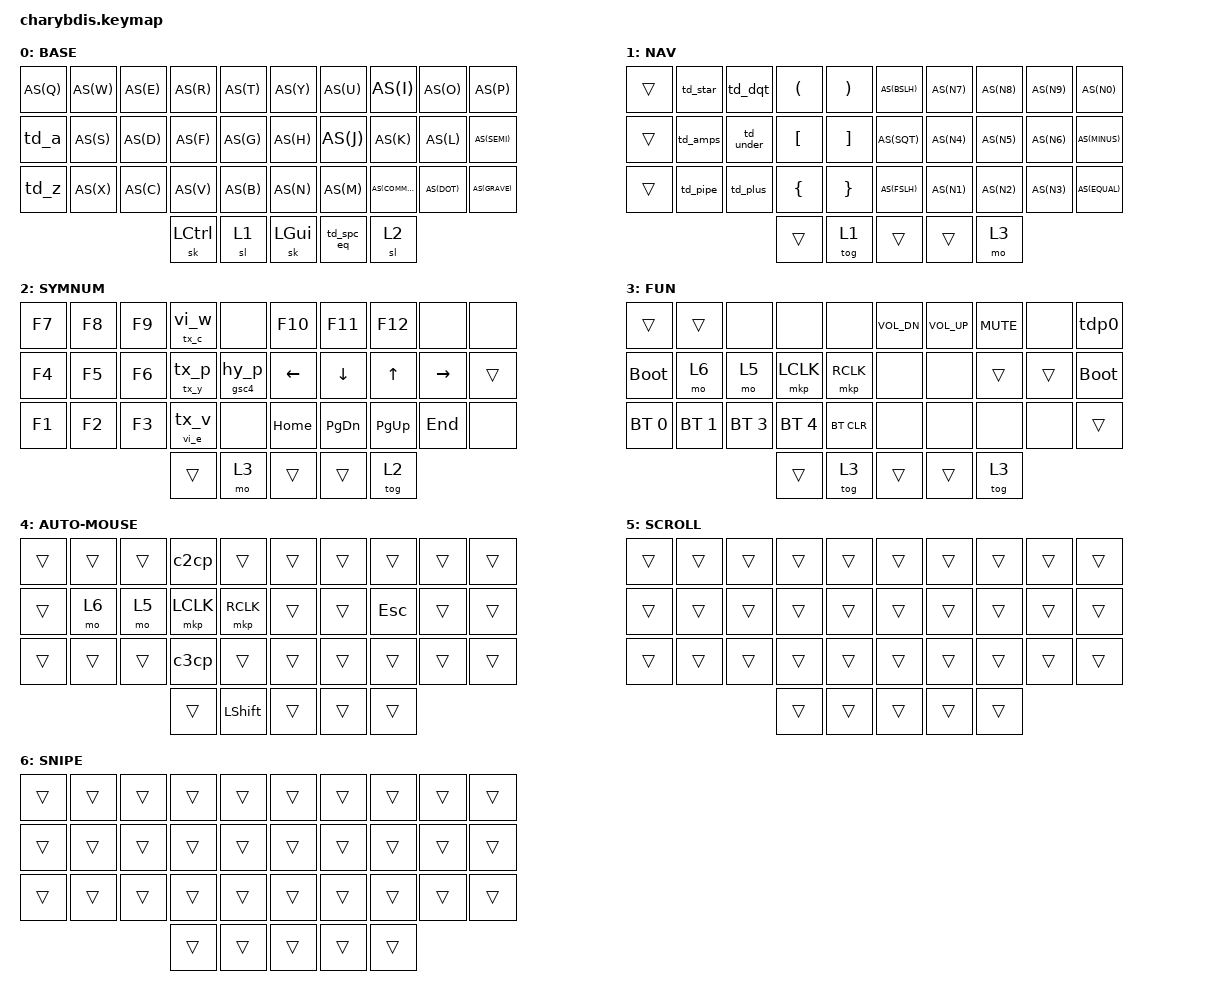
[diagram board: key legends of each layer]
#include <behaviors/mouse_keys.dtsi>
#include <behaviors.dtsi>
#include <dt-bindings/zmk/bt.h>
#include <dt-bindings/zmk/keys.h>
#include <dt-bindings/zmk/mouse.h>
#include <dt-bindings/zmk/outputs.h>

#define AS(keycode) &as LS(keycode) keycode     // Autoshift Macro

#define SPC_WRAP(macro_name, content) \
        macro_name: macro_name { \
            compatible = "zmk,behavior-macro"; \
            #binding-cells = <0>; \
            wait-ms = <25>; \
            tap-ms = <25>; \
            bindings = <&macro_tap &kp SPACE content &kp SPACE>; \
        }

#define TD_SPC_WRAP_2(td_name, prime_key, macro_name) \
        td_name: td_name { \
            compatible = "zmk,behavior-tap-dance"; \
            #binding-cells = <0>; \
            tapping-term-ms = <200>; \
            bindings = <&kp prime_key>, <&macro_name>; \
        }

// Longer time out for oneshot keys
&sl {
    release-after-ms = <2000>;
};
&sk {
    release-after-ms = <2000>;
};

/ {
    chosen { zmk,matrix_transform = &five_column_transform; };
};

/ {
    macros {
        vi_w: vi_w {
            label = "VIM_SAVE";
            compatible = "zmk,behavior-macro";
            #binding-cells = <0>;
            wait-ms = <40>;
            tap-ms = <40>;
            bindings
                = <&macro_tap &kp ESC &kp COLON &kp W &kp ENTER>
                ;
        };
        vi_e: vi_e {
            label = "VIM_RELOADE_BUFFER";
            compatible = "zmk,behavior-macro";
            #binding-cells = <0>;
            wait-ms = <40>;
            tap-ms = <40>;
            bindings
                = <&macro_tap &kp ESC &kp COLON &kp E &kp LS(N1) &kp ENTER>
                ;
        };
        tx_c: tx_c {
            label = "TMUX_COPY_MODE";
            compatible = "zmk,behavior-macro";
            #binding-cells = <0>;
            wait-ms = <40>;
            tap-ms = <40>;
            bindings
                = <&macro_tap &kp LC(B) &kp LBKT>
                ;
        };
        tx_p: tx_p {
            label = "TMUX_PREV_PANE";
            compatible = "zmk,behavior-macro";
            #binding-cells = <0>;
            wait-ms = <40>;
            tap-ms = <40>;
            bindings
                = <&macro_tap &kp LC(B) &kp SEMI>
                ;
        };
        tx_y: tx_y {
            label = "TMUX_PREV_PANE_MAX";
            compatible = "zmk,behavior-macro";
            #binding-cells = <0>;
            wait-ms = <40>;
            tap-ms = <40>;
            bindings
                = <&macro_tap &kp LC(B) &kp Y>
                ;
        };
        tx_v: tx_v {
            label = "TMUX_PREV_PASTE";
            compatible = "zmk,behavior-macro";
            #binding-cells = <0>;
            wait-ms = <40>;
            tap-ms = <40>;
            bindings
                = <&macro_tap &kp LC(B) &kp COLON &kp P &kp A &kp ENTER>
                ;
        };
        hy_p: hy_p {
            label = "HYPER_P";
            compatible = "zmk,behavior-macro";
            #binding-cells = <0>;
            wait-ms = <40>;
            tap-ms = <40>;
            bindings
                = <&macro_tap &kp LG(LA(LS(LC(P))))>
                ;
        };
        gsc4: gsc4 {
            label = "MAC_OS_SCREENSHOT_4";
            compatible = "zmk,behavior-macro";
            #binding-cells = <0>;
            wait-ms = <40>;
            tap-ms = <40>;
            bindings
                = <&macro_tap &kp LG(LS(LC(N4)))>
                ;
        };
        pri0: pri0 {
            label = "PRIVATE_KEY_SEQ_0";
            compatible = "zmk,behavior-macro";
            #binding-cells = <0>;
            wait-ms = <40>;
            tap-ms = <40>;
            bindings
                = <&macro_tap 
                    &kp LS(Z) &kp C &kp T &kp D &kp L &kp A &kp M &kp N &kp U 
                    &kp X &kp D &kp E &kp X &kp D &kp Z &kp O &kp G &kp D &kp M 
                    &kp Z>
                ;
        };
        pri1: pri1 {
            label = "PRIVATE_KEY_SEQ_1";
            compatible = "zmk,behavior-macro";
            #binding-cells = <0>;
            wait-ms = <40>;
            tap-ms = <40>;
            bindings
                = <&macro_tap &kp BSPC>
                , <&macro_wait_time 3500>
                , <&pri0>
                ;
        };
        pri2: pri2 {
            label = "PRIVATE_KEY_SEQ_2";
            compatible = "zmk,behavior-macro";
            #binding-cells = <0>;
            wait-ms = <40>;
            tap-ms = <40>;
            bindings
                = <&macro_tap 
                    &kp C &kp T &kp D &kp L &kp A &kp M &kp N &kp U 
                    &kp Z>
                ;
        };
        // Click and copy
        c2cp: c2cp {
            label = "DOUBLE_CLICK_CMD_C";
            compatible = "zmk,behavior-macro";
            #binding-cells = <0>;
            wait-ms = <40>;
            bindings
                = <&macro_tap &mkp LCLK &mkp LCLK>
                , <&macro_wait_time 300>
                , <&macro_tap &kp LG(C)>
                ;
        };
        c3cp: c3cp {
            label = "TRIPLE_CLICK_CMD_C";
            compatible = "zmk,behavior-macro";
            #binding-cells = <0>;
            wait-ms = <40>;
            bindings
                = <&macro_tap &mkp LCLK &mkp LCLK &mkp LCLK>
                , <&macro_wait_time 300>
                , <&macro_tap &kp LG(C)>
                ;
        };

        SPC_WRAP(spc_eq, &kp EQUAL);
        SPC_WRAP(spc_mi, &kp MINUS);
        SPC_WRAP(spc_pl, &kp PLUS);
        SPC_WRAP(spc_st, &kp STAR);
        SPC_WRAP(spc_am, &kp AMPS &kp AMPS);
        SPC_WRAP(spc_pi, &kp PIPE &kp PIPE);

        tri_dqt: tri_dqt {
            label = "TRIPLE_DOUBLE_QUOTE";
            compatible = "zmk,behavior-macro";
            #binding-cells = <0>;
            wait-ms = <40>;
            bindings = <&macro_tap &kp DQT &kp DQT &kp DQT>;
        };
    };

    behaviors {
        tdsc: tap_dance_toggle_scroll {
            label = "TD_TOGGLE_SCROLL";
            compatible = "zmk,behavior-tap-dance";
            #binding-cells = <0>;
            tapping-term-ms = <175>;
            bindings = <&mo 5>, <&tog 5>;
        };

        tdsn: tap_dance_toggle_sniping {
            label = "TD_TOGGLE_SNIPING";
            compatible = "zmk,behavior-tap-dance";
            #binding-cells = <0>;
            tapping-term-ms = <175>;
            bindings = <&mo 6>, <&tog 6>;
        };

        as: auto_shift {
            label = "AUTO_SHIFT";
            compatible = "zmk,behavior-hold-tap";
            #binding-cells = <2>;
            tapping_term_ms = <155>;
            quick_tap_ms = <154>;
            flavor = "tap-preferred";
            bindings = <&kp>, <&kp>;
        };

        ht_r: hold_tap_at_r {
            label = "HOLD_TAP_AT_R";
            compatible = "zmk,behavior-hold-tap";
            #binding-cells = <2>;
            tapping_term_ms = <155>;
            quick_tap_ms = <120>;
            flavor = "tap-preferred";
            bindings = <&tx_c>, <&vi_w>;
        };

        ht_f: hold_tap_at_f {
            label = "HOLD_TAP_AT_F";
            compatible = "zmk,behavior-hold-tap";
            #binding-cells = <2>;
            tapping_term_ms = <155>;
            quick_tap_ms = <120>;
            flavor = "tap-preferred";
            bindings = <&tx_y>, <&tx_p>;
        };

        ht_v: hold_tap_at_v {
            label = "HOLD_TAP_AT_V";
            compatible = "zmk,behavior-hold-tap";
            #binding-cells = <2>;
            tapping_term_ms = <155>;
            quick_tap_ms = <120>;
            flavor = "tap-preferred";
            bindings = <&vi_e>, <&tx_v>;
        };

        ht_g: hold_tap_at_g {
            label = "HOLD_TAP_AT_G";
            compatible = "zmk,behavior-hold-tap";
            #binding-cells = <2>;
            tapping_term_ms = <155>;
            quick_tap_ms = <120>;
            flavor = "tap-preferred";
            bindings = <&gsc4>, <&hy_p>;
        };

        ht_p: hold_tap_at_p {
            label = "HOLD_TAP_AT_P";
            compatible = "zmk,behavior-hold-tap";
            #binding-cells = <2>;
            tapping_term_ms = <155>;
            quick_tap_ms = <120>;
            flavor = "tap-preferred";
            bindings = <&pri2>, <&pri0>;
        };

        tdp0: tap_dance_private_seq_02 {
            label = "TD_PRIVATE_SEQ_02";
            compatible = "zmk,behavior-tap-dance";
            #binding-cells = <0>;
            tapping-term-ms = <175>;
            bindings = <&none>, <&ht_p 0 0>;
        };
        
        ht_32: hold_tri_click_tap_double_click {
            label = "HOLD_TRI_TAP_DOUBLE";
            compatible = "zmk,behavior-hold-tap";
            #binding-cells = <2>;
            tapping-term-ms = <200>;
            flavor = "tap-preferred";
            bindings = <&c3cp>, <&c2cp>;
        };

        TD_SPC_WRAP_2(td_spc_eq, SPACE, spc_eq);
        TD_SPC_WRAP_2(td_under, UNDER, spc_mi);
        TD_SPC_WRAP_2(td_plus, PLUS, spc_pl);
        TD_SPC_WRAP_2(td_dqt, DQT, tri_dqt);
        TD_SPC_WRAP_2(td_star, STAR, spc_st);
        TD_SPC_WRAP_2(td_amps, AMPS, spc_am);
        TD_SPC_WRAP_2(td_pipe, PIPE, spc_pi);
        
        td_z: tap_dance_z_alt {
            compatible = "zmk,behavior-tap-dance";
            #binding-cells = <0>;
            tapping-term-ms = <175>;
            bindings = <&mt LALT Z>, <&as Z LS(Z)>;
        };
        td_a: tap_dance_a_shift {
            compatible = "zmk,behavior-tap-dance";
            #binding-cells = <0>;
            tapping-term-ms = <175>;
            bindings = <&mt LSHFT A>, <&as A LS(A)>;
        };
    };

    combos {
        compatible = "zmk,combos";
        // Tmux
        combo_ctrl_b {
            timeout-ms = <25>;
            key-positions = <12 2>; // D, E
            bindings = <&kp LC(B)>;
        };

        // Track ball and mouse clicks
        combo_mo_scroll {
            timeout-ms = <25>;
            key-positions = <11 1>; // S, W
            bindings = <&tdsc>; //<&mo 5>;
        };
        combo_mo_snipe {
            timeout-ms = <25>;
            key-positions = <8 18>; // O, L
            bindings = <&tdsn>; //<&mo 6>;
        };
        combo_left_click {
            timeout-ms = <25>;
            key-positions = <12 13>; // D, F
            bindings = <&mkp LCLK>;
        };
        combo_right_click {
            timeout-ms = <25>;
            key-positions = <13 14>; // F, G
            bindings = <&mkp RCLK>;
        };
        combo_tog_3 {
            timeout-ms = <25>;
            key-positions = <11 21>; // S, X
            bindings = <&tog 3>;
        };


        // Enter/ESC ...
        combo_enter {
            timeout-ms = <25>;
            key-positions = <7 17>; // I, K
            bindings = <&kp ENTER>;
        };
        combo_shift_enter {
            timeout-ms = <25>;
            key-positions = <17 27>; // K, COMMA
            bindings = <&kp LS(ENTER)>;
        };
        combo_tab {
            timeout-ms = <25>;
            key-positions = <16 26>; // J, M
            bindings = <&kp TAB>;
        };
        combo_caps_word {
            timeout-ms = <25>;
            key-positions = <15 25>; // H, N
            bindings = <&caps_word>;
        };
        combo_esc_1 {
            timeout-ms = <25>;
            key-positions = <13 23>; // F, V
            bindings = <&kp ESC>;
        };
        combo_esc_2 {
            timeout-ms = <25>;
            key-positions = <11 18>; // S, L
            bindings = <&kp ESC>;
        };
        combo_bspc {
            timeout-ms = <25>;
            key-positions = <3 13>; // R, F
            bindings = <&kp BSPC>;
        };
        combo_del {
            timeout-ms = <25>;
            key-positions = <4 14>; // T, G
            bindings = <&kp DEL>;
        };

        // Lock screen (MacOS)
        combo_cmd_ctrl_q {
            timeout-ms = <25>;
            key-positions = <13 23 14 24>; // F, V, G, B
            bindings = <&kp LG(LC(Q))>;
        };

        combo_alt_space {
            timeout-ms = <25>;
            key-positions = <16 17>; // J, K
            bindings = <&kp LA(SPACE)>;
        };

        combo_ctrl_alt_space {
            timeout-ms = <25>;
            key-positions = <14 24>; // G, B
            bindings = <&kp LA(LC(SPACE))>;
        };

        combo_ctrl_alt_shift_space {
            timeout-ms = <25>;
            key-positions = <18 28>; // L, .(DOT)
            bindings = <&kp LA(LC(LS(SPACE)))>;
        };

        combo_private_seq_1 {
            timeout-ms = <25>;
            key-positions = <15 16 25 26>; // H, J, N, M
            bindings = <&pri1>;
        };
        
        // Oneshot mods
        combo_shift {
            timeout-ms = <25>;
            key-positions = <11 13>; // S, F
            bindings = <&sk LSHFT>;
        };
        combo_alt {
            timeout-ms = <25>;
            key-positions = <17 18>; // K, L
            bindings = <&sk LALT>;
        };
        // M, A is used for alt-shift-down
        combo_gui_shift {
            timeout-ms = <25>;
            key-positions = <26 11>; // M, S
            bindings = <&sk LG(LSHFT)>;
        };
        combo_gui_alt {
            timeout-ms = <40>;
            key-positions = <26 13>; // M, F
            bindings = <&sk LG(LALT)>;
        };
        combo_gui_ctrl {
            timeout-ms = <40>;
            key-positions = <26 22>; // M, C
            bindings = <&sk LG(LCTRL)>;
        };
        combo_gui_shift_alt {
            timeout-ms = <30>;
            key-positions = <26 12>; // M, D
            bindings = <&sk LG(LS(LALT))>;
        };
        combo_gui_shift_ctrl {
            timeout-ms = <40>;
            key-positions = <26 21>; // M, X
            bindings = <&sk LG(LS(LCTRL))>;
        };
        combo_gui_alt_ctrl {
            timeout-ms = <40>;
            key-positions = <26 23>; // M, V
            bindings = <&sk LG(LA(LCTRL))>;
        };
        combo_hyper {
            timeout-ms = <40>;
            key-positions = <26 1>; // M, W
            bindings = <&sk LG(LS(LA(LCTRL)))>;
        };
        combo_meh {
            timeout-ms = <40>;
            key-positions = <23 15>; // V, H
            bindings = <&sk LS(LA(LCTRL))>;
        };
        combo_alt_ctrl {
            timeout-ms = <40>;
            key-positions = <23 16>; // V, J
            bindings = <&sk LA(LCTRL)>;
        };
        combo_alt_shift {
            timeout-ms = <40>;
            key-positions = <23 17>; // V, K
            bindings = <&sk LA(LSHFT)>;
        };
        combo_shift_ctrl {
            timeout-ms = <40>;
            key-positions = <23 18>; // V, L
            bindings = <&sk LC(LSHFT)>;
        };
        /*
        // Alt / Shift with arrows
        combo_alt_left_arrow {
            timeout-ms = <40>;
            key-positions = <10 15>; // A, H
            bindings = <&kp LA(LEFT)>;
        };
        combo_alt_down_arrow {
            timeout-ms = <40>;
            key-positions = <10 16>; // A, J
            bindings = <&kp LA(DOWN)>;
        };
        combo_alt_up_arrow {
            timeout-ms = <40>;
            key-positions = <10 17>; // A, K
            bindings = <&kp LA(UP)>;
        };
        combo_alt_right_arrow {
            timeout-ms = <40>;
            key-positions = <10 18>; // A, L
            bindings = <&kp LA(RIGHT)>;
        };
        combo_alt_shift_left_arrow {
            timeout-ms = <40>;
            key-positions = <10 25>; // A, N
            bindings = <&kp LA(LS(LEFT))>;
        };
        combo_alt_shift_down_arrow {
            timeout-ms = <40>;
            key-positions = <10 26>; // A, M
            bindings = <&kp LA(LS(DOWN))>;
        };
        combo_alt_shift_up_arrow {
            timeout-ms = <40>;
            key-positions = <10 27>; // A, ,
            bindings = <&kp LA(LS(UP))>;
        };
        combo_alt_shift_right_arrow {
            timeout-ms = <40>;
            key-positions = <10 28>; // A, .
            bindings = <&kp LA(LS(RIGHT))>;
        };

        combo_alt_backspace {
            timeout-ms = <40>;
            key-positions = <10 19>; // A, ;
            bindings = <&kp LA(BSPC)>;
        };
        */
    };

    keymap {
        compatible = "zmk,keymap";

        BASE {
            bindings = <
AS(Q)    AS(W)   AS(E)     AS(R)         AS(T)            AS(Y)        AS(U)          AS(I)      AS(O)    AS(P)
&td_a    AS(S)   AS(D)     AS(F)         AS(G)            AS(H)        AS(J)          AS(K)      AS(L)    AS(SEMI)
&td_z    AS(X)   AS(C)     AS(V)         AS(B)            AS(N)        AS(M)          AS(COMMA)  AS(DOT)  AS(GRAVE)
                            &sk LCTRL  &sl 1     &sk LGUI      &td_spc_eq  &sl 2
            >;
        };

        NAV {
            bindings = <
&trans     &td_star    &td_dqt       &kp LPAR      &kp RPAR      AS(BSLH)   AS(N7)     AS(N8)     AS(N9)     AS(N0)
&trans     &td_amps    &td_under     &kp LBKT      &kp RBKT      AS(SQT)    AS(N4)     AS(N5)     AS(N6)     AS(MINUS)
&trans     &td_pipe    &td_plus      &kp LBRC      &kp RBRC      AS(FSLH)   AS(N1)     AS(N2)     AS(N3)     AS(EQUAL)
                            &trans        &tog 1        &trans        &trans     &mo 3
            >;
        };

        SYMNUM {
            bindings = <
&kp F7  &kp F8   &kp F9        &ht_r 0 0      &none        &kp F10   &kp F11      &kp F12   &none      &none
&kp F4  &kp F5   &kp F6        &ht_f 0 0      &ht_g 0 0    &kp LEFT  &kp DOWN     &kp UP    &kp RIGHT  &trans
&kp F1  &kp F2   &kp F3        &ht_v 0 0      &none        &kp HOME  &kp PG_DN    &kp PG_UP &kp END    &none
                                   &trans        &mo 3          &trans       &trans    &tog 2
            >;
        };

        FUN {
            bindings = <
&trans        &trans        &none         &none         &none         &kp C_VOL_DN &kp C_VOL_UP &kp C_MUTE    &none         &tdp0
&bootloader   &mo 6         &mo 5         &mkp LCLK     &mkp RCLK     &none        &none        &trans        &trans        &bootloader
&bt BT_SEL 0  &bt BT_SEL 1  &bt BT_SEL 3  &bt BT_SEL 4  &bt BT_CLR    &none        &none        &none         &none         &trans
                         &trans        &tog 3     &trans        &trans       &tog 3
            >;
        };

        AUTO-MOUSE {
            bindings = <
&trans  &trans  &trans     &c2cp       &trans       &trans  &trans  &trans  &trans  &trans
&trans  &mo 6   &mo 5      &mkp LCLK   &mkp RCLK    &trans  &trans  &kp ESC &trans  &trans
&trans  &trans  &trans     &c3cp       &trans       &trans  &trans  &trans  &trans  &trans
                        &trans     &kp LSHFT  &trans       &trans  &trans
            >;
        };

        SCROLL {
            bindings = <
&trans  &trans  &trans   &trans  &trans       &trans  &trans  &trans  &trans  &trans
&trans  &trans  &trans   &trans  &trans       &trans  &trans  &trans  &trans  &trans
&trans  &trans  &trans   &trans  &trans       &trans  &trans  &trans  &trans  &trans
                        &trans   &trans  &trans       &trans  &trans
            >;
        };

        SNIPE {
            bindings = <
&trans  &trans  &trans   &trans  &trans       &trans  &trans  &trans  &trans  &trans
&trans  &trans  &trans   &trans  &trans       &trans  &trans  &trans  &trans  &trans
&trans  &trans  &trans   &trans  &trans       &trans  &trans  &trans  &trans  &trans
                        &trans   &trans  &trans       &trans  &trans
            >;
        };

    };
};
